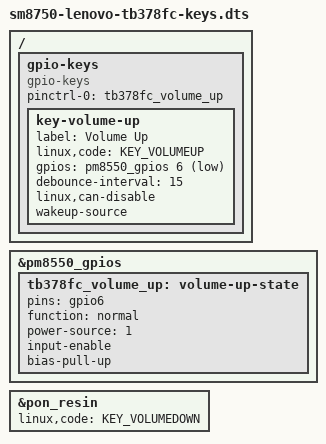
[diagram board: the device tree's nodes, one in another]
// SPDX-License-Identifier: BSD-3-Clause
/* Volume wiring verified against this TB378FC's native device tree. */
#include "sm8750-lenovo-tb378fc-wifi.dts"

/ {
    gpio-keys {
        compatible = "gpio-keys";
        pinctrl-names = "default";
        pinctrl-0 = <&tb378fc_volume_up>;

        key-volume-up {
            label = "Volume Up";
            linux,code = <KEY_VOLUMEUP>;
            gpios = <&pm8550_gpios 6 GPIO_ACTIVE_LOW>;
            debounce-interval = <15>;
            linux,can-disable;
            wakeup-source;
        };
    };
};

&pm8550_gpios {
    tb378fc_volume_up: volume-up-state {
        pins = "gpio6";
        function = "normal";
        power-source = <1>;
        input-enable;
        bias-pull-up;
    };
};

&pon_resin {
    linux,code = <KEY_VOLUMEDOWN>;
    status = "okay";
};
